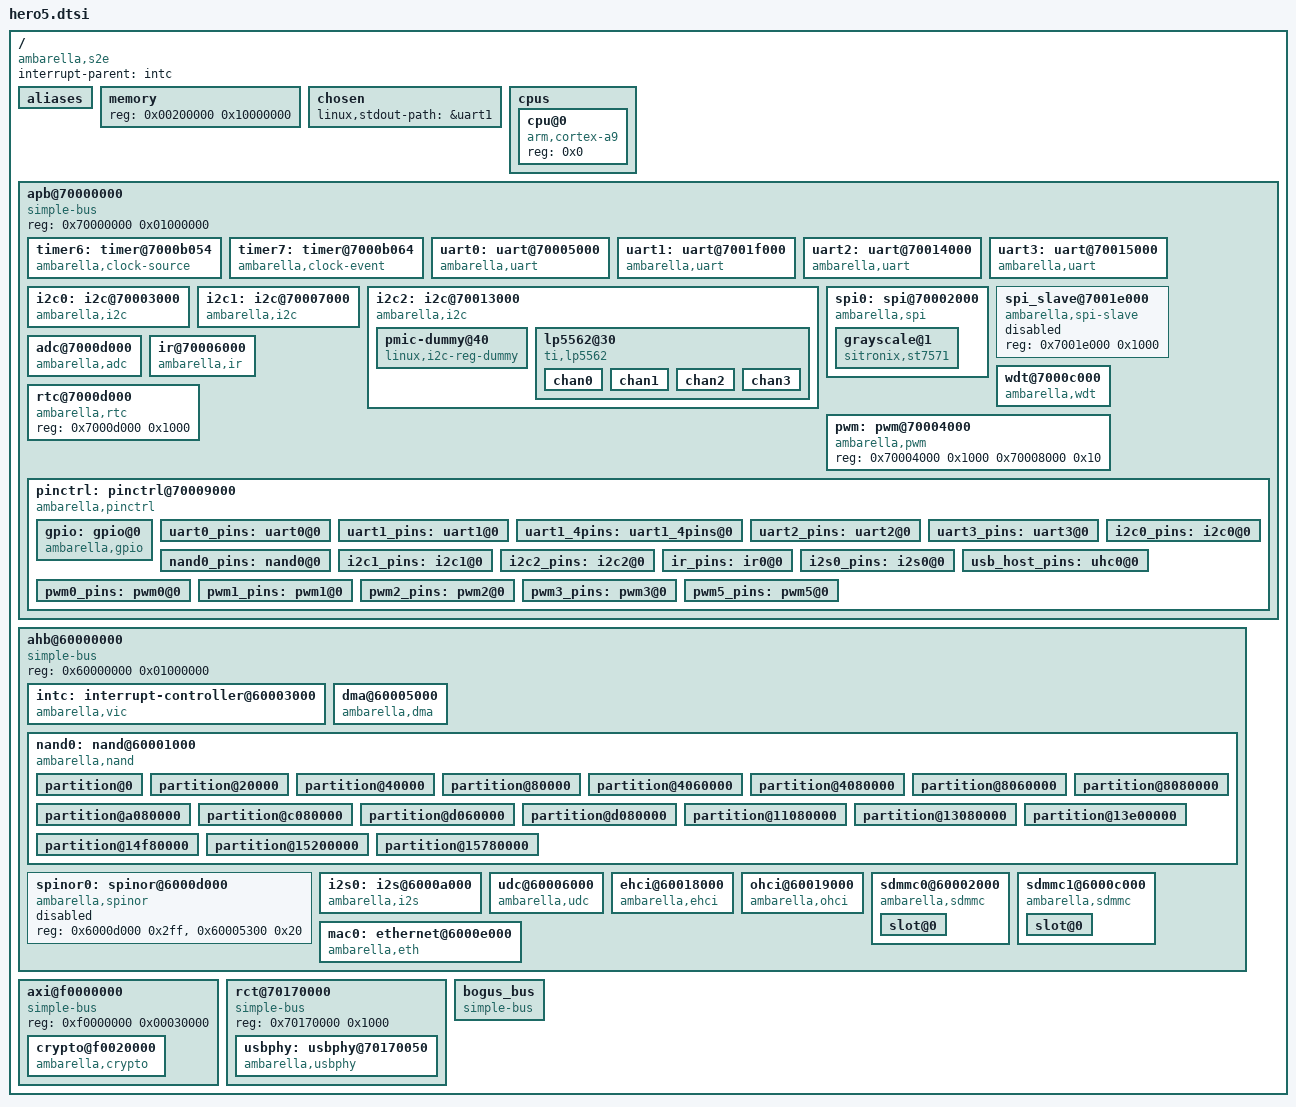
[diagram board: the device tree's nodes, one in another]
/*
 * Copyright (C) 2013 Ambarella,Inc. - http://www.ambarella.com/
 * Copyright (C) 2016 evilwombat
 *
 * Author: Cao Rongrong <rrcao@ambarella.com>
 *
 * This program is free software; you can redistribute it and/or modify
 * it under the terms of the GNU General Public License version 2 as
 * published by the Free Software Foundation.
 */

/ {
	#address-cells = <1>;
	#size-cells = <1>;
	compatible = "ambarella,s2e";
	interrupt-parent = <&intc>;

	aliases {
		serial0 = &uart0;
		serial1 = &uart1;
		serial2 = &uart2;
		serial3 = &uart3;
		nand = &nand0;
		i2c0 = &i2c0;
		i2c1 = &i2c1;
		i2c2 = &i2c2;
		spi0 = &spi0;
		ethernet0 = &mac0;
	};

	memory {
		device_type = "memory";
		reg = <0x00200000 0x10000000>;
	};

	chosen {
		linux,stdout-path = &uart1;
	};

	cpus {
		#address-cells = <1>;
		#size-cells = <0>;
		cpu@0 {
			device_type = "cpu";
			compatible = "arm,cortex-a9";
			reg = <0x0>;
		};
	};

	apb@70000000 {	/* APB */
		compatible = "simple-bus";
		#address-cells = <1>;
		#size-cells = <1>;
		reg = <0x70000000 0x01000000>;
		ranges;

		timer6: timer@7000b054 {
			compatible = "ambarella,clock-source";
			reg = <0x7000b054 0x10 0x7000b030 0x4>;
			interrupts = <61 0x1>;
			ctrl-offset = <20>; /* bit offset in timer-ctrl reg */
		};

		timer7: timer@7000b064 {
			compatible = "ambarella,clock-event";
			reg = <0x7000b064 0x10 0x7000b030 0x4>;
			interrupts = <62 0x1>;
			ctrl-offset = <24>; /* bit offset in timer-ctrl reg */
		};

		/* timer6 and timer5 */
                /*
		local_timer: timer@7000b044 {
			compatible = "ambarella,local-clock-event";
			reg = <0x7000b044 0x10 0x7000b030 0x4 0x7000b034 0x10 0x7000b030 0x4>;
			interrupts = <60 0x1 59 0x1>;
			ctrl-offset = <16 12>;
		};
                */

		uart0: uart@70005000 {
			compatible = "ambarella,uart";
			reg = <0x70005000 0x100>;
			interrupts = <9 0x04>;
			pinctrl-names = "default";
			pinctrl-0 = <&uart0_pins>;
			/* amb,tx-fifo-fix; */
		};

		uart1: uart@7001f000 {
			compatible = "ambarella,uart";
			reg = <0x7001f000 0x100>;
			interrupts = <25 0x04>;
			amb,msr-used;	/* use Modem Status Register */
			/* amb,tx-fifo-fix; */
		};

		uart2: uart@70014000 {
			compatible = "ambarella,uart";
			reg = <0x70014000 0x100>;
			interrupts = <91 0x04>;
			status = "ok";
			amb,msr-used;	/* use Modem Status Register */
			/* amb,tx-fifo-fix; */
		};

		uart3: uart@70015000 {
			compatible = "ambarella,uart";
			reg = <0x70015000 0x100>;
			interrupts = <92 0x04>;
			status = "ok";
			amb,msr-used;	/* use Modem Status Register */
			/* amb,tx-fifo-fix; */
		};

		i2c0: i2c@70003000 {
			compatible = "ambarella,i2c";
			#address-cells = <1>;
			#size-cells = <0>;
			reg = <0x70003000 0x1000>;
			interrupts = <19 0x04>;
			pinctrl-names = "default";
			pinctrl-0 = <&i2c0_pins>;
			clock-frequency = <100000>;
			amb,i2c-class = <0x81>;
			amb,bulk-num = <60>;
			status = "ok";
	        };

		i2c1: i2c@70007000 {
			compatible = "ambarella,i2c";
			#address-cells = <1>;
			#size-cells = <0>;
			reg = <0x70007000 0x1000>;
			interrupts = <36 0x04>;
			pinctrl-names = "default";
			pinctrl-0 = <&i2c1_pins>;
			clock-frequency = <100000>;
			amb,i2c-class = <0x08>;
			amb,bulk-num = <60>;
			status = "ok";
	        };

		i2c2: i2c@70013000 {
			compatible = "ambarella,i2c";
			#address-cells = <1>;
			#size-cells = <0>;
			reg = <0x70013000 0x1000>;
			interrupts = <90 0x04>;
			pinctrl-names = "default";
			pinctrl-0 = <&i2c2_pins>;
			clock-frequency = <100000>;
			amb,i2c-class = <0x81>;
			amb,bulk-num = <60>;
			status = "ok";

			pmic-dummy@40 {
				compatible = "linux,i2c-reg-dummy";
				reg = <0x40>;
				linux,reg-data = /bits/8 <
					0x00 0x30  0x01 0xd0  0x02 0xf8  0x03 0x3c
					0x04 0x9c  0x05 0x9a  0x06 0xcc  0x07 0x00
					0x08 0x73  0x09 0x73  0x0a 0x7f  0x0b 0x0c
					0x0c 0x0a  0x0d 0x00  0x0e 0x81  0x0f 0x00
					0x10 0x4f  0x11 0x3c  0x12 0x00  0x13 0x00
					0x14 0x00  0x15 0xcc  0x16 0x0c  0x19 0x07
					0x1a 0x07  0x1b 0x00  0x1c 0xee  0x1d 0x2e
					0x1e 0x26  0x1f 0x0a  0x20 0xd8  0x21 0xdb
					0x22 0x0a  0x23 0x00  0x24 0x00  0x25 0x00
					0x26 0x00  0x27 0x19  0x28 0x00  0x29 0x00
					0x2a 0x00  0x2b 0x00  0x2c 0x00  0x2d 0x01
					0x2e 0x02  0x2f 0x00  0x30 0x00  0x31 0x04
					0x32 0x1d  0x33 0x00  0x34 0x00  0x35 0x18
					0x36 0x00  0x37 0x00  0x38 0x01  0x39 0x00
					0x3a 0x80  0x3b 0x20  0x3c 0x0f  0x3d 0xe7
					0x3e 0x02  0x3f 0x12  0x40 0x12  0x41 0x85
					0x42 0x2f  0x43 0x01  0x44 0x00  0x45 0x00
					0x46 0x00  0x47 0x00  0x48 0x00  0x49 0x00
					0x4a 0x00  0x4f 0x80  0x50 0x11  0x51 0x2e
					0x52 0x1e  0x54 0x20  0x55 0x7f  0x56 0x1f
					0x57 0x00  0x58 0x00  0x59 0x01  0x5a 0x00
					0x5b 0x00  0x5c 0x00  0x5d 0x8b  0x60 0x00
					0x61 0xff  0x62 0x00  0x63 0x00  0x69 0x00
					0x6a 0x00  0x70 0xe5  0x71 0x1f  0x72 0xff
					0x73 0xf7  0x74 0xff  0x75 0x0f  0x7d 0x00
					0x7e 0x1d  0x7f 0x8b  0x80 0xf7  0x81 0xad
					0x82 0xb1  0x83 0x3f  0x84 0xdf  0x85 0x27
					0x86 0x51  0x87 0x8a  0x88 0x92  0x89 0x04
					0x8a 0xd4  0x8b 0x26  0x8c 0x00  0x8d 0x10
					0x8e 0x1d  0x8f 0x1d  0x90 0x12  0x91 0x01>;
			};

			lp5562@30 {
				compatible = "ti,lp5562";
				reg = <0x30>;
				clock-mode = /bits/8 <2>;

				chan0 {
					chan-name = "back";
					led-cur = /bits/ 8 <0x20>;
					max-cur = /bits/ 8 <0x60>;
				};

				chan1 {
					chan-name = "front_red";
					led-cur = /bits/ 8 <0x20>;
					max-cur = /bits/ 8 <0x60>;
				};

				chan2 {
					chan-name = "front_blue";
					led-cur = /bits/ 8 <0x20>;
					max-cur = /bits/ 8 <0x60>;
				};

				chan3 {
					chan-name = "bottom";
					led-cur = /bits/ 8 <0x20>;
					max-cur = /bits/ 8 <0x60>;
				};
			};
	        };

		spi0: spi@70002000 {
			compatible = "ambarella,spi";
			#address-cells = <1>;
			#size-cells = <0>;
			reg = <0x70002000 0x1000>;
			interrupts = <20 0x4>;
			amb,clk-name = "gclk_ssi";
			amb,clk-freq = <60000000>;
			cs-gpios = <&gpio 5 0>, <&gpio 6 0>;

			grayscale@1 {
				compatible = "sitronix,st7571";
				reg = <1>;
				spi-max-frequency = <1000000>;
				sitronix,reset-gpio = <&gpio 13 0>;
			};
		};

		spi_slave@7001e000 {
			compatible = "ambarella,spi-slave";
			reg = <0x7001e000 0x1000>;
			/* interrupts = <26 0x4>; */
			status = "disabled";
		};

		adc@7000d000 {
			compatible = "ambarella,adc";
			reg = <0x7000d000 0x1000>;
			interrupts = <34 0x4>;
			clock-frequency = <3000000>;
		};

		ir@70006000 {
			compatible = "ambarella,ir";
			reg = <0x70006000 0x1000>;
			/* interrupts = <22 0x4>; */
			pinctrl-names = "default";
			pinctrl-0 = <&ir_pins>;
		};

		wdt@7000c000 {
			compatible = "ambarella,wdt";
			reg = <0x7000c000 0x1000>;
			/* interrupts = <21 0x4>; */
			timeout-sec = <15>;
		};

		rtc@7000d000 {
			compatible = "ambarella,rtc";
			reg = <0x7000d000 0x1000>;
		};

		pwm: pwm@70004000 {
			compatible = "ambarella,pwm";
			reg = <0x70004000 0x1000 0x70008000 0x10>;
			#pwm-cells = <3>;
		};

		pinctrl: pinctrl@70009000 {
			compatible = "ambarella,pinctrl", "simple-bus";
			#address-cells = <1>;
			#size-cells = <0>;
			reg = <0x70009000 0x1000>,
			      <0x7000a000 0x1000>,
			      <0x7000e000 0x1000>,
			      <0x70010000 0x1000>,
			      <0x70011000 0x1000>;
			reg-names = "gpio0", "gpio1", "gpio2", "gpio3", "gpio4";
			#gpio-range-cells = <3>;

			gpio: gpio@0 {
				compatible = "ambarella,gpio";
				/* gpio interrupts to vic */
				interrupts = <10 0x0>,
					     <11 0x0>,
					     <30 0x0>,
					     <29 0x0>,
					     <48 0x0>;
				gpio-controller;
				#gpio-cells = <2>;
				gpio-ranges = <&pinctrl 0 0 160>;
				interrupt-controller;
				#interrupt-cells = <2>;
			};

			uart0_pins: uart0@0 {
				reg = <0>;
				amb,pinmux-ids = <0x100e 0x100f>;
			};

			uart1_pins: uart1@0 {
				reg = <0>;
				amb,pinmux-ids = <0x1034 0x1035>,
						 /* virtual pins, just for configuration purpose */
						 <0x1021 0x0022 0x1032 0x1033>;
			};

			uart1_4pins: uart1_4pins@0 {
				reg = <0>;
				amb,pinmux-ids = <0x1032 0x1033 0x1034 0x1035>,
						 /* virtual pins, just for configuration purpose */
						 <0x1021 0x0022>;
			};

			uart2_pins: uart2@0 {
				reg = <0>;
				amb,pinmux-ids = <0x100a 0x1012>;
			};

			uart3_pins: uart3@0 {
				reg = <0>;
				amb,pinmux-ids = <0x1013 0x1014>;
			};

			nand0_pins: nand0@0 {
				reg = <0>;
				amb,pinmux-ids = <0x1027>; /* just WP is shared with GPIO */
			};

			i2c0_pins: i2c0@0 {
				reg = <0>;
				amb,pinmux-ids = <0x1000 0x1001>;
			};

			i2c1_pins: i2c1@0 {
				reg = <0>;
				amb,pinmux-ids = <0x1056 0x1057>;
			};

			i2c2_pins: i2c2@0 {
				reg = <0>;
				amb,pinmux-ids = <0x1024 0x1025>,
						 /* virtual pins, just for configuration purpose */
						 <0x1011>;
			};

			ir_pins: ir0@0 {
				reg = <0>;
				amb,pinmux-ids = <0x1023>;
			};

			i2s0_pins: i2s0@0 {
				reg = <0>;
				amb,pinmux-ids = <0x104d 0x104e 0x104f 0x1050 0x1051>,
						 /* virtual pins, just for configuration purpose.*/
						 <0x0064 0x0065>;
			};

			usb_host_pins: uhc0@0 {
				reg = <0>;
				amb,pinmux-ids = /* <0x1007 0x1009>, */
						 /* virtual pins, just for configuration purpose.
						   EHCI_PRT_PWR and APP_PRT_OVCURR share the hw
						   mode with SPI enable pin. */
						 <0x1060 0x1061>;
			};

			pwm0_pins: pwm0@0 {
				reg = <0>;
				amb,pinmux-ids = <0x102d>;
			};

			pwm1_pins: pwm1@0 {
				reg = <0>;
				amb,pinmux-ids = <0x102e>;
			};

			pwm2_pins: pwm2@0 {
				reg = <0>;
				amb,pinmux-ids = <0x1032>,
						/* virtual pins, just for
						   configuration purpose.*/
						 <0x0021 0x0022>;
			};

			pwm3_pins: pwm3@0 {
				reg = <0>;
				amb,pinmux-ids = <0x1033>,
						/* virtual pins, just for
						   configuration purpose.*/
						 <0x0022 0x0003>;
			};

			pwm5_pins: pwm5@0 {
				reg = <0>;
				amb,pinmux-ids = <0x1010>;
			};
		};
	};

	ahb@60000000 {	/* AHB */
		compatible = "simple-bus";
		#address-cells = <1>;
		#size-cells = <1>;
		reg = <0x60000000 0x01000000>;
		ranges;

		intc: interrupt-controller@60003000 {
			compatible = "ambarella,vic";
			interrupt-controller;
			#interrupt-cells = <2>;
			reg = <0x60003000 0x1000>,
			      <0x60010000 0x1000>,
			      <0x6001c000 0x1000>;
		};

		dma@60005000 {
			compatible = "ambarella,dma";
			reg = <0x60005000 0x1000>;
			interrupts = <15 0x4>;
			amb,copy-align = <0>;
			/* support pause/resume/stop */
			amb,support-prs;
		};

		nand0: nand@60001000 {
			compatible = "ambarella,nand";
			#address-cells = <1>;
			#size-cells = <1>;
			reg = <0x60001000 0x1000>, /* fio reg address */
			      <0x60012000 0x1000>, /* fdma reg address */
			      <0x60000000 0x4>;    /* fifo base */
			interrupts = <16 0x04>,	/* fio_cmd_irq */
				     <17 0x04>,	/* fio_dma_irq */
				     <33 0x04>;	/* fdma_irq */
			pinctrl-names = "default";
			pinctrl-0 = <&nand0_pins>;
			nand-on-flash-bbt;
			/* amb,enable-wp; */
			/* amb,soft-ecc = <1>; */

			partition@0 {
				reg = <0x0 0x20000>;
				label = "BST_PTB1";
			};

			partition@20000 {
				reg = <0x20000 0x20000>;
				label = "PTB2";
			};

			partition@40000 {
				reg = <0x40000 0x40000>;
				label = "BLD";
			};

			partition@80000 {
				reg = <0x80000 0x3FE0000>;
				label = "FWUP";
			};

			partition@4060000 {
				reg = <0x4060000 0x20000>;
				label = "DTB1_RTOS";
			};

			partition@4080000 {
				reg = <0x4080000 0x03fe0000>;
				label = "RTOS";
			};

			partition@8060000 {
				reg = <0x8060000 0x20000>;
				label = "DTB2_RTOS";
			};

			partition@8080000 {
				reg = <0x8080000 0x02000000>;
				label = "DSP";
			};

			partition@a080000 {
				reg = <0xa080000 0x2000000>;
				label = "ROMFS";
			};

			partition@c080000 {
				reg = <0xc080000 0xFE0000>;
				label = "Linux";
			};

			partition@d060000 {
				reg = <0xd060000 0x20000>;
				label = "DTB_Linux";
			};

			partition@d080000 {
				reg = <0xd080000 0x4000000>;
				label = "rootfs";
			};

			partition@11080000 {
				reg = <0x11080000 0x2000000>;
				label = "hiber";
			};

			partition@13080000 {
				reg = <0x13080000 0xd80000>;
				label = "vrec_idx";
			};

			partition@13e00000 {
				reg = <0x13e00000 0x1180000>;
				label = "cal";
				read-only;
			};

			partition@14f80000 {
				reg = <0x14f80000 0x280000>;
				label = "settings";
			};

			partition@15200000 {
				reg = <0x15200000 0x580000>;
				label = "drv_a";
			};

			partition@15780000 {
				reg = <0x15780000 0x2180000>;
				label = "drv_b";
			};

		};

		spinor0: spinor@6000d000 {
			compatible = "ambarella,spinor";
			reg = <0x6000d000 0x2ff>, /* spi nor controller */
			      <0x60005300 0x20>;  /* dma reg */
			status = "disabled";
		};

		i2s0: i2s@6000a000 {
			compatible = "ambarella,i2s";
			reg = <0x6000a000 0x1000>;
			pinctrl-names = "default";
			pinctrl-0 = <&i2s0_pins>;
			amb,i2s-channels = <2>;
			amb,default-mclk = <12288000>;
		};

		udc@60006000 {
			compatible = "ambarella,udc";
			reg = <0x60006000 0x2000 0x70170088 0x4>;
			interrupts = <4 0x04>;
			amb,usbphy = <&usbphy>;
		};

		ehci@60018000 {
			compatible = "ambarella,ehci";
			reg = <0x60018000 0x1000>;
			interrupts = <73 0x04>;
			amb,usbphy = <&usbphy>;
		};

		ohci@60019000 {
			compatible = "ambarella,ohci";
			reg = <0x60019000 0x1000>;
			interrupts = <89 0x04>;
			amb,usbphy = <&usbphy>;
		};

		sdmmc0@60002000 {
			compatible = "ambarella,sdmmc";
			#address-cells = <1>;
			#size-cells = <0>;
			reg = <0x60002000 0x1000>,
			      <0x60001000 0x80>, /* fio reg address */
			      <0x701701d0 0x4>;
			interrupts = <18 0x4>;
			amb,clk-name = "gclk_sd";
			amb,wait-tmo = <2500>; /* in millisecond */
			amb,max-blk-size = <524288>; /* valid value: 4K<<n */
			amb,timing-magic = <1>; /* see codes for its meaning */

			slot@0 {
				reg = <0>;
				max-frequency = <48000000>;
				bus-width = <8>;
				amb,caps-adma;
				amb,caps-ddr;
				cap-sdio-irq;
				no-1-8-v;
			};
		};

		sdmmc1@6000c000 {
			compatible = "ambarella,sdmmc";
			#address-cells = <1>;
			#size-cells = <0>;
			reg = <0x6000c000 0x1000>,
			      <0x60001000 0x80>, /* fio reg address */
			      <0x701701d0 0x4>;
			interrupts = <52 0x4>;
			amb,clk-name = "gclk_sdio";
			amb,wait-tmo = <2500>; /* in millisecond */
			amb,max-blk-size = <524288>; /* valid value: 4K<<n */
			amb,timing-magic = <2>; /* see codes for its meaning */

			slot@0 {
				reg = <0>;
				max-frequency = <48000000>;
				bus-width = <8>;
				amb,caps-adma;
				amb,caps-ddr;
				cap-sdio-irq;
			};
		};

		mac0: ethernet@6000e000 {
			compatible = "ambarella,eth";
			#address-cells = <1>;
			#size-cells = <0>;
			reg = <0x6000e000 0x2000>;
			interrupts = <27 0x4>;
			amb,support-gmii;
			amb,tx-ring-size = <64>;
			amb,rx-ring-size = <64>;
			amb,ipc-rx;
		};
	};

	axi@f0000000 {	/* AXI */
		compatible = "simple-bus";
		#address-cells = <1>;
		#size-cells = <1>;
		reg = <0xf0000000 0x00030000>;
		ranges;

		crypto@f0020000 {
			compatible = "ambarella,crypto";
			reg = <0xf0020000 0x8000>;
			interrupts = <44 0x1>, <45 0x1>, <47 0x1>, <88 0x1>;
			interrupt-names = "aes-irq", "des-irq", "md5-irq", "sha1-irq";
			amb,cap-md5-sha1;
			amb,data-swap;
			amb,reg-64bit;
		};
	};

	rct@70170000 {
		compatible = "simple-bus";
		#address-cells = <1>;
		#size-cells = <1>;
		reg = <0x70170000 0x1000>;
		ranges;

		usbphy: usbphy@70170050 {
			compatible = "ambarella,usbphy";
			reg = <0x70170050 0x4 0x6001b00c 0x4 0x70170088 0x4>;
			amb,host-phy-num = <2>;
		};
	};

	bogus_bus {
		compatible = "simple-bus";
		#address-cells = <1>;
		#size-cells = <0>;
	};
};
